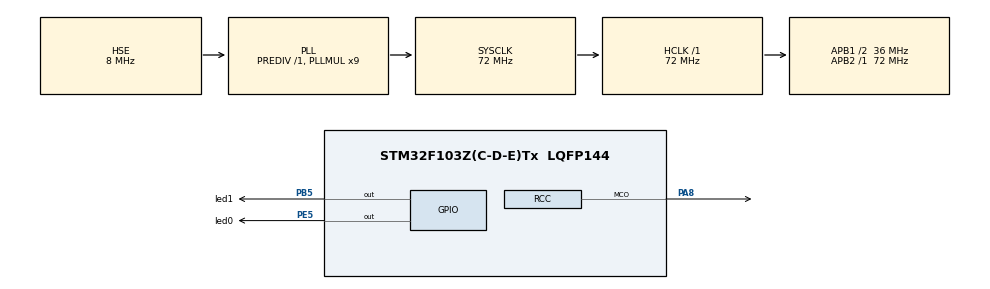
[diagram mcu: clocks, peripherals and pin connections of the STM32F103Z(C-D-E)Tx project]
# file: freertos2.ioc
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Mcu.Family=STM32F1
Mcu.Name=STM32F103Z(C-D-E)Tx
Mcu.Package=LQFP144
NVIC.PriorityGroup=NVIC_PRIORITYGROUP_4
OSC_IN.Mode=HSE-External-Oscillator
OSC_IN.Signal=RCC_OSC_IN
OSC_OUT.Mode=HSE-External-Oscillator
OSC_OUT.Signal=RCC_OSC_OUT
PA13.Mode=Serial_Wire
PA13.Signal=SYS_JTMS-SWDIO
PA14.Mode=Serial_Wire
PA14.Signal=SYS_JTCK-SWCLK
PA8.Mode=Clock-out
PA8.Signal=RCC_MCO
PB5.GPIO_Label=led1
PB5.Signal=GPIO_Output
PE5.GPIO_Label=led0
PE5.Signal=GPIO_Output
ProjectManager.HeapSize=0x200
ProjectManager.StackSize=0x400
ProjectManager.TargetToolchain=Makefile
RCC.AHBFreq_Value=72000000
RCC.APB1CLKDivider=RCC_HCLK_DIV2
RCC.APB1Freq_Value=36000000
RCC.APB1TimFreq_Value=72000000
RCC.APB2Freq_Value=72000000
RCC.APB2TimFreq_Value=72000000
RCC.HCLKFreq_Value=72000000
RCC.PLLMUL=RCC_PLL_MUL9
RCC.PLLSourceVirtual=RCC_PLLSOURCE_HSE
RCC.RCC_MCOSource=RCC_MCO1SOURCE_HSE
RCC.SYSCLKFreq_VALUE=72000000
RCC.SYSCLKSource=RCC_SYSCLKSOURCE_PLLCLK
RCC.TimSys_Div=SYSTICK_CLKSOURCE_HCLK_DIV8
RCC.USBFreq_Value=72000000
board=custom

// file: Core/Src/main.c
/* USER CODE BEGIN Header */
/**
  ******************************************************************************
  * @file           : main.c
  * @brief          : Main program body
  ******************************************************************************
  * @attention
  *
  * Copyright (c) 2024 STMicroelectronics.
  * All rights reserved.
  *
  * This software is licensed under terms that can be found in the LICENSE file
  * in the root directory of this software component.
  * If no LICENSE file comes with this software, it is provided AS-IS.
  *
  ******************************************************************************
  */
/* USER CODE END Header */
#include "main.h"
#include "gpio.h"

/* USER CODE BEGIN Includes */
#include "FreeRTOS.h"
#include "task.h"
/* USER CODE END Includes */

/* USER CODE BEGIN PV */
/* Idle task control block and stack */
static StaticTask_t Idle_TCB;
static StackType_t  Idle_Stack[configMINIMAL_STACK_SIZE];

/* Timer task control block and stack */
static StaticTask_t Timer_TCB;
static StackType_t  Timer_Stack[configTIMER_TASK_STACK_DEPTH];

/* USER CODE END PV */

void SystemClock_Config(void);

/* USER CODE BEGIN 0 */

void task_one(void* param) {
  for(;;) {
    HAL_GPIO_TogglePin(led0_GPIO_Port, led0_Pin);
    vTaskDelay(1000);
  }
}

void task_two(void* param) {
  for(;;) {
    HAL_GPIO_TogglePin(led1_GPIO_Port, led1_Pin);
    vTaskDelay(500);
  }
}

void vApplicationGetIdleTaskMemory (StaticTask_t **ppxIdleTaskTCBBuffer, StackType_t **ppxIdleTaskStackBuffer, uint32_t *pulIdleTaskStackSize) {
  *ppxIdleTaskTCBBuffer   = &Idle_TCB;
  *ppxIdleTaskStackBuffer = &Idle_Stack[0];
  *pulIdleTaskStackSize   = (uint32_t)configMINIMAL_STACK_SIZE;
}

/*
  vApplicationGetTimerTaskMemory gets called when configSUPPORT_STATIC_ALLOCATION
  equals to 1 and is required for static memory allocation support.
*/
void vApplicationGetTimerTaskMemory (StaticTask_t **ppxTimerTaskTCBBuffer, StackType_t **ppxTimerTaskStackBuffer, uint32_t *pulTimerTaskStackSize) {
  *ppxTimerTaskTCBBuffer   = &Timer_TCB;
  *ppxTimerTaskStackBuffer = &Timer_Stack[0];
  *pulTimerTaskStackSize   = (uint32_t)configTIMER_TASK_STACK_DEPTH;
}

/* USER CODE END 0 */

int main(void)
{

  /* MCU Configuration--------------------------------------------------------*/

  /* Reset of all peripherals, Initializes the Flash interface and the Systick. */
  HAL_Init();

  /* Configure the system clock */
  SystemClock_Config();

  /* Initialize all configured peripherals */
  MX_GPIO_Init();
  /* USER CODE BEGIN 2 */
  xTaskCreate(task_one, "ONE", 128 * sizeof(void*), 0, 1, 0);
  xTaskCreate(task_two, "TWO", 128 * sizeof(void*), 0, 1, 0);
  vTaskStartScheduler();
  /* USER CODE END 2 */

  /* Infinite loop */
  /* USER CODE BEGIN WHILE */
  int a = 0;
  while (1)
  {
    /* USER CODE END WHILE */
    ++a;
  }
}

void SystemClock_Config(void)
{
  RCC_OscInitTypeDef RCC_OscInitStruct = {0};
  RCC_ClkInitTypeDef RCC_ClkInitStruct = {0};

  /** Initializes the RCC Oscillators according to the specified parameters
  * in the RCC_OscInitTypeDef structure.
  */
  RCC_OscInitStruct.OscillatorType = RCC_OSCILLATORTYPE_HSE;
  RCC_OscInitStruct.HSEState = RCC_HSE_ON;
  RCC_OscInitStruct.HSEPredivValue = RCC_HSE_PREDIV_DIV1;
  RCC_OscInitStruct.HSIState = RCC_HSI_ON;
  RCC_OscInitStruct.PLL.PLLState = RCC_PLL_ON;
  RCC_OscInitStruct.PLL.PLLSource = RCC_PLLSOURCE_HSE;
  RCC_OscInitStruct.PLL.PLLMUL = RCC_PLL_MUL9;
  if (HAL_RCC_OscConfig(&RCC_OscInitStruct) != HAL_OK)
  {
    Error_Handler();
  }

  /** Initializes the CPU, AHB and APB buses clocks
  */
  RCC_ClkInitStruct.ClockType = RCC_CLOCKTYPE_HCLK|RCC_CLOCKTYPE_SYSCLK
                              |RCC_CLOCKTYPE_PCLK1|RCC_CLOCKTYPE_PCLK2;
  RCC_ClkInitStruct.SYSCLKSource = RCC_SYSCLKSOURCE_PLLCLK;
  RCC_ClkInitStruct.AHBCLKDivider = RCC_SYSCLK_DIV1;
  RCC_ClkInitStruct.APB1CLKDivider = RCC_HCLK_DIV2;
  RCC_ClkInitStruct.APB2CLKDivider = RCC_HCLK_DIV1;

  if (HAL_RCC_ClockConfig(&RCC_ClkInitStruct, FLASH_LATENCY_2) != HAL_OK)
  {
    Error_Handler();
  }
  HAL_RCC_MCOConfig(RCC_MCO, RCC_MCO1SOURCE_HSE, RCC_MCODIV_1);
}

void Error_Handler(void)
{
  __disable_irq();
  while (1)
  {
  }
}
